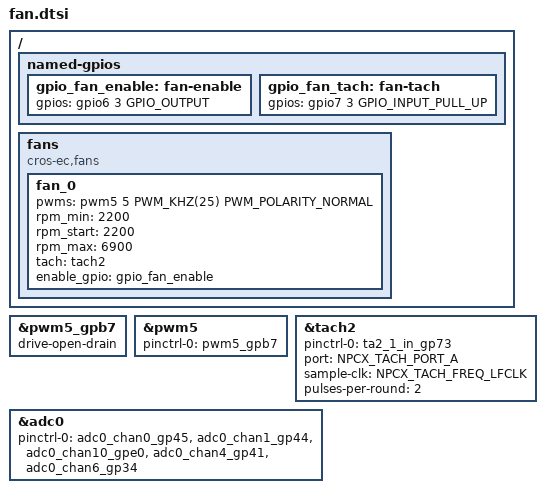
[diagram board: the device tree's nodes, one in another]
/* Copyright 2022 The ChromiumOS Authors
 * Use of this source code is governed by a BSD-style license that can be
 * found in the LICENSE file.
 */

/ {
	named-gpios {
		gpio_fan_enable: fan-enable {
			gpios = <&gpio6 3 GPIO_OUTPUT>;
		};
		gpio_fan_tach: fan-tach {
			gpios = <&gpio7 3 GPIO_INPUT_PULL_UP>;
		};
	};

	fans {
		compatible = "cros-ec,fans";

		fan_0 {
			pwms = <&pwm5 5 PWM_KHZ(25) PWM_POLARITY_NORMAL>;
			rpm_min = <2200>;
			rpm_start = <2200>;
			rpm_max = <6900>;
			tach = <&tach2>;
			enable_gpio = <&gpio_fan_enable>;
		};
	};
};

&pwm5_gpb7 {
	drive-open-drain;
};

&pwm5 {
	status = "okay";
	pinctrl-0 = <&pwm5_gpb7>;
	pinctrl-names = "default";
};

/* Tachometer for fan speed measurement */
&tach2 {
	status = "okay";
	pinctrl-0 = <&ta2_1_in_gp73>;
	pinctrl-names = "default";
	port = <NPCX_TACH_PORT_A>; /* port-A is selected */
	sample-clk = <NPCX_TACH_FREQ_LFCLK>; /* Use LFCLK as sampling clock */
	pulses-per-round = <2>; /* number of pulses per round of encoder */
};

/* Remove temp_sensor_4 ADC channel as it doesn't exist on the ORB */
&adc0 {
	pinctrl-0 = <&adc0_chan0_gp45
		&adc0_chan1_gp44
		&adc0_chan10_gpe0
		&adc0_chan4_gp41
		&adc0_chan6_gp34>;
};
